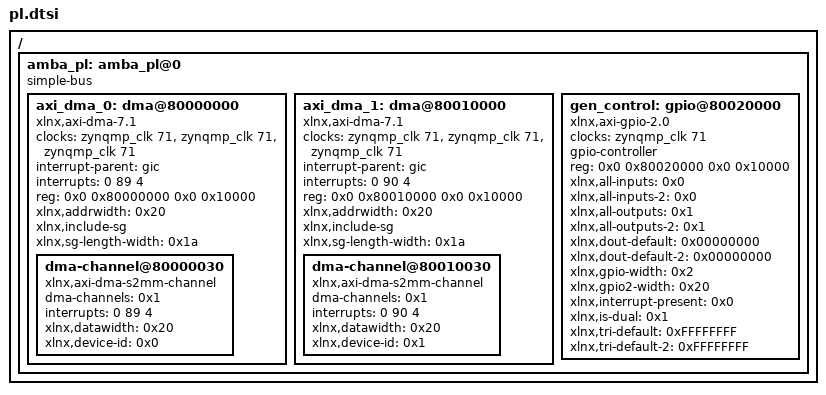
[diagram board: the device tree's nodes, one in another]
/*
 * CAUTION: This file is automatically generated by Xilinx.
 * Version: XSCT 2022.2
 * Today is: Thu Jun  8 12:07:21 2023
 */


/ {
	amba_pl: amba_pl@0 {
		#address-cells = <2>;
		#size-cells = <2>;
		compatible = "simple-bus";
		ranges ;
		axi_dma_0: dma@80000000 {
			#dma-cells = <1>;
			clock-names = "s_axi_lite_aclk", "m_axi_sg_aclk", "m_axi_s2mm_aclk";
			clocks = <&zynqmp_clk 71>, <&zynqmp_clk 71>, <&zynqmp_clk 71>;
			compatible = "xlnx,axi-dma-7.1", "xlnx,axi-dma-1.00.a";
			interrupt-names = "s2mm_introut";
			interrupt-parent = <&gic>;
			interrupts = <0 89 4>;
			reg = <0x0 0x80000000 0x0 0x10000>;
			xlnx,addrwidth = <0x20>;
			xlnx,include-sg ;
			xlnx,sg-length-width = <0x1a>;
			dma-channel@80000030 {
				compatible = "xlnx,axi-dma-s2mm-channel";
				dma-channels = <0x1>;
				interrupts = <0 89 4>;
				xlnx,datawidth = <0x20>;
				xlnx,device-id = <0x0>;
			};
		};
		axi_dma_1: dma@80010000 {
			#dma-cells = <1>;
			clock-names = "s_axi_lite_aclk", "m_axi_sg_aclk", "m_axi_s2mm_aclk";
			clocks = <&zynqmp_clk 71>, <&zynqmp_clk 71>, <&zynqmp_clk 71>;
			compatible = "xlnx,axi-dma-7.1", "xlnx,axi-dma-1.00.a";
			interrupt-names = "s2mm_introut";
			interrupt-parent = <&gic>;
			interrupts = <0 90 4>;
			reg = <0x0 0x80010000 0x0 0x10000>;
			xlnx,addrwidth = <0x20>;
			xlnx,include-sg ;
			xlnx,sg-length-width = <0x1a>;
			dma-channel@80010030 {
				compatible = "xlnx,axi-dma-s2mm-channel";
				dma-channels = <0x1>;
				interrupts = <0 90 4>;
				xlnx,datawidth = <0x20>;
				xlnx,device-id = <0x1>;
			};
		};
		gen_control: gpio@80020000 {
			#gpio-cells = <2>;
			clock-names = "s_axi_aclk";
			clocks = <&zynqmp_clk 71>;
			compatible = "xlnx,axi-gpio-2.0", "xlnx,xps-gpio-1.00.a";
			gpio-controller ;
			reg = <0x0 0x80020000 0x0 0x10000>;
			xlnx,all-inputs = <0x0>;
			xlnx,all-inputs-2 = <0x0>;
			xlnx,all-outputs = <0x1>;
			xlnx,all-outputs-2 = <0x1>;
			xlnx,dout-default = <0x00000000>;
			xlnx,dout-default-2 = <0x00000000>;
			xlnx,gpio-width = <0x2>;
			xlnx,gpio2-width = <0x20>;
			xlnx,interrupt-present = <0x0>;
			xlnx,is-dual = <0x1>;
			xlnx,tri-default = <0xFFFFFFFF>;
			xlnx,tri-default-2 = <0xFFFFFFFF>;
		};
	};
};
